# AltaRiscv register map
File version: 1.0
Registers are 32-bit, read-write, reset 0x0 unless marked. A register's access mark holds for its fields unless they carry their own. Offsets are from the block's base; [hi:lo] are bit positions; {n}, {i} and the like mark numbered series.

## CAN0 — CAN registers
Base 0x4002A000
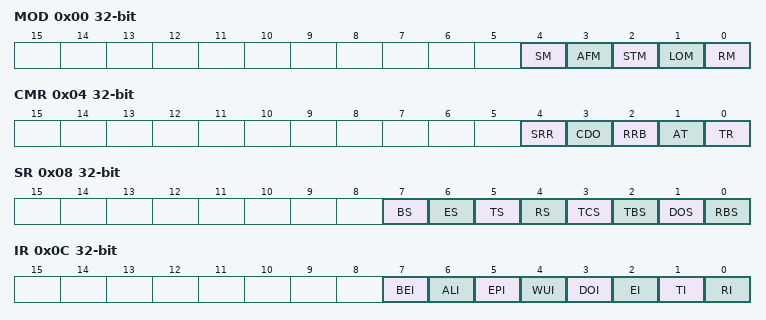
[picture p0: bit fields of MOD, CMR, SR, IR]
0x00 MOD — Mode register
  [4] SM — Sleep Mode
  [3] AFM — Acceptance Filter Mode
    0=Dual; 1=Single
  [2] STM — Self Test Mode
  [1] LOM — Listen Only Mode
  [0] RM — Reset Mode
0x04 CMR wo — Command register
  [4] SRR — Self Reception Request
  [3] CDO — Clear Data Overrun
  [2] RRB — Release Receive Buffer
  [1] AT — Abort Transmission
  [0] TR — Transmission Request
0x08 SR ro — Status register
  [7] BS — Bus Status
  [6] ES — Error Status
  [5] TS — Transmit Status
  [4] RS — Receive Status
  [3] TCS — Transmission Complete Status
  [2] TBS — Transmit Buffer Status
  [1] DOS — Data Overrun Status
  [0] RBS — Receive Buffer Status
0x0C IR ro — Interrupt register
  [7] BEI — Bus Error Interrupt
  [6] ALI — Arbitration Lost Interrupt
  [5] EPI — Error Passive Interrupt
  [4] WUI — Wake-Up Interrupt
  [3] DOI — Data Overrun Interrupt
  [2] EI — Error Warning Interrupt
  [1] TI — Transmit Interrupt
  [0] RI — Receive Interrupt
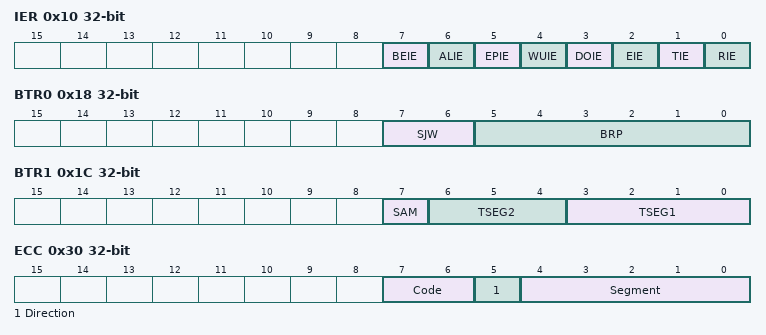
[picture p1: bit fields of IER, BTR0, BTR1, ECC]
0x10 IER — Interrupt enable register
  [7] BEIE — Bus Error Interrupt Enable
  [6] ALIE — Arbitration Lost Interrupt Enable
  [5] EPIE — Error Passive Interrupt Enable
  [4] WUIE — Wake-Up Interrupt Enable
  [3] DOIE — Data Overrun Interrupt Enable
  [2] EIE — Error Warning Interrupt Enable
  [1] TIE — Transmit Interrupt Enable
  [0] RIE — Receive Interrupt Enable
0x18 BTR0 — Bus Timing 0
  [7:6] SJW — Synchronization Jump Width
  [5:0] BRP — Baud Rate Prescaler
0x1C BTR1 — Bus Timing 1
  [7] SAM — Sampling
  [6:4] TSEG2 — Time Segment 2
  [3:0] TSEG1 — Time Segment 1
0x20 OCR — Output Control Register
  [1:0] OCR
    2=Normal Output Mode
0x2C ALC ro — Arbitration Lost Capture
  [4:0] ALC
0x30 ECC ro — Error Code Capture
  [7:6] Code — Error code
    0=Bit error; 1=Form error; 2=Stuff error; 3=Other error
  [5] Direction — When is error occured
    0=TX; 1=RX
  [4:0] Segment — Segment code
0x34 EWLR — Error Warning Limit
  [7:0] EWLR
0x38 RXERR — Receive Error Counter
  [7:0] RXERR
0x3C TXERR — Transmit Error Counter
  [7:0] TXERR
0x40 FRAME — Transfer Frame Information
  [7:0] FRAME
0x40 ACR[0] (alternate view of FRAME) — Acceptance Code Register
  [7:0] ACR[0] — Acceptance Code Register 0
{0x40+4i} ACR[{i}] (i=1..3) — Acceptance Code Register
  [7:0] ACR[{i}] — Acceptance Code Register {i}
{0x44+4i} DATA[{i}] (alternate view of ACR[{i+1}]) (i=0..2) — Transfer Data Information
  [7:0] DATA[{i}] — Transfer Data Information {i}
{0x50+4i} AMR[{i}] (i=0..3) — Acceptance Mask Register
  [7:0] AMR[{i}] — Acceptance Mask Register {i}
{0x44+4i} DATA[{i}] (alternate view of AMR[{i-3}]) (i=3..6) — Transfer Data Information
  [7:0] DATA[{i}] — Transfer Data Information {i}
{0x44+4i} DATA[{i}] (i=7..11) — Transfer Data Information
  [7:0] DATA[{i}] — Transfer Data Information {i}
0x74 RMC ro — Receive Message Counter
  [4:0] RMC
0x78 RBSA — Receive Buffer Start Address
  [5:0] RBSA
0x180 TX_FRAME ro — Transmit Frame Information
  [7:0] TX_FRAME
{0x184+4i} TX_DATA[{i}] ro (i=0..11) — Transmit Data Information
  [7:0] TX_DATA[{i}] — Transmit Data Information {i}

## I2C0 — I2C registers
Base 0x4002B000
Same registers: I2C1 0x4002C000
0x00 PRERLO — Prescaler register lo-byte
  [7:0] PRERLO
0x04 PRERHI — Prescaler register hi-byte
  [7:0] PRERHI
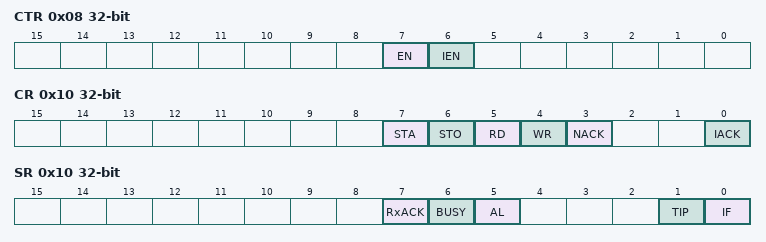
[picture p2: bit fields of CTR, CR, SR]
0x08 CTR — Control register
  [7] EN — Core enable
  [6] IEN — Interrupt enable
0x0C RXR ro — Receive register
  [7:0] RXR
0x0C TXR wo (alternate view of RXR) — Transmit register
  [7:0] TXR
0x10 CR wo — Command register
  [7] STA — Generate (repeated) start condition
  [6] STO — Generate stop condition
  [5] RD — Read from slave
  [4] WR — Write to slave
  [3] NACK — When a receiver, send ACK(0) or NACK(1)
  [0] IACK — Interrupt acknowledge
0x10 SR ro (alternate view of CR) — Status register
  [7] RxACK — Received acknowledge from slave
    0=ACK; 1=NACK
  [6] BUSY — I2C bus busy
  [5] AL — Arbitration lost
  [1] TIP — Transfer in progress
  [0] IF — Interrupt flag. Set when one byte transfer is done or arbitration lost
